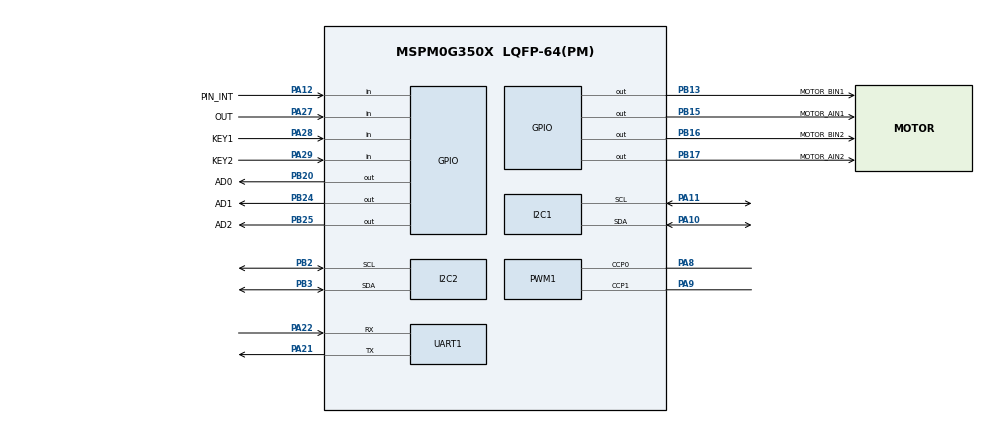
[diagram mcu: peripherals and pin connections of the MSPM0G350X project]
/**
 * @cliArgs --device "MSPM0G350X" --part "Default" --package "LQFP-64(PM)" --product "mspm0_sdk@2.10.00.04"
 * @versions {"tool":"1.26.2+4477"}
 */

/**
 * Import the modules used in this configuration.
 */
const GPIO   = scripting.addModule("/ti/driverlib/GPIO", {}, false);
const GPIO1  = GPIO.addInstance();
const GPIO2  = GPIO.addInstance();
const GPIO3  = GPIO.addInstance();
const GPIO4  = GPIO.addInstance();
const GPIO5  = GPIO.addInstance();
const GPIO6  = GPIO.addInstance();
const I2C    = scripting.addModule("/ti/driverlib/I2C", {}, false);
const I2C1   = I2C.addInstance();
const I2C2   = I2C.addInstance();
const PWM    = scripting.addModule("/ti/driverlib/PWM", {}, false);
const PWM1   = PWM.addInstance();
const SYSCTL = scripting.addModule("/ti/driverlib/SYSCTL");
const TIMER  = scripting.addModule("/ti/driverlib/TIMER", {}, false);
const TIMER1 = TIMER.addInstance();
const UART   = scripting.addModule("/ti/driverlib/UART", {}, false);
const UART1  = UART.addInstance();

/**
 * Write custom configuration values to the imported modules.
 */
GPIO1.$name                              = "KEY_INPUT";
GPIO1.port                               = "PORTA";
GPIO1.associatedPins.create(2);
GPIO1.associatedPins[0].$name            = "KEY1";
GPIO1.associatedPins[0].direction        = "INPUT";
GPIO1.associatedPins[0].internalResistor = "PULL_UP";
GPIO1.associatedPins[0].pin.$assign      = "PA28";
GPIO1.associatedPins[1].$name            = "KEY2";
GPIO1.associatedPins[1].direction        = "INPUT";
GPIO1.associatedPins[1].internalResistor = "PULL_UP";
GPIO1.associatedPins[1].pin.$assign      = "PA29";

const Board = scripting.addModule("/ti/driverlib/Board", {}, false);

GPIO2.$name                         = "MOTOR_AIN";
GPIO2.port                          = "PORTB";
GPIO2.associatedPins.create(2);
GPIO2.associatedPins[0].$name       = "MOTOR_AIN1";
GPIO2.associatedPins[0].pin.$assign = "PB15";
GPIO2.associatedPins[1].$name       = "MOTOR_AIN2";
GPIO2.associatedPins[1].pin.$assign = "PB17";

GPIO3.$name                         = "MOTOR_BIN";
GPIO3.port                          = "PORTB";
GPIO3.associatedPins.create(2);
GPIO3.associatedPins[0].$name       = "MOTOR_BIN1";
GPIO3.associatedPins[0].pin.$assign = "PB13";
GPIO3.associatedPins[1].$name       = "MOTOR_BIN2";
GPIO3.associatedPins[1].pin.$assign = "PB16";

GPIO4.$name                         = "Gray_Address";
GPIO4.port                          = "PORTB";
GPIO4.associatedPins.create(3);
GPIO4.associatedPins[0].$name       = "AD0";
GPIO4.associatedPins[0].pin.$assign = "PB20";
GPIO4.associatedPins[1].$name       = "AD1";
GPIO4.associatedPins[1].pin.$assign = "PB24";
GPIO4.associatedPins[2].$name       = "AD2";
GPIO4.associatedPins[2].pin.$assign = "PB25";

GPIO5.$name                         = "Gray_OUT";
GPIO5.port                          = "PORTA";
GPIO5.associatedPins[0].$name       = "OUT";
GPIO5.associatedPins[0].direction   = "INPUT";
GPIO5.associatedPins[0].pin.$assign = "PA27";

GPIO6.$name                         = "GPIO_MPU6050";
GPIO6.port                          = "PORTA";
GPIO6.associatedPins[0].$name       = "PIN_INT";
GPIO6.associatedPins[0].direction   = "INPUT";
GPIO6.associatedPins[0].pin.$assign = "PA12";

I2C1.$name                             = "I2C_OLED";
I2C1.basicEnableController             = true;
I2C1.basicControllerStandardBusSpeed   = "Fast";
I2C1.peripheral.$assign                = "I2C0";
I2C1.peripheral.sdaPin.$assign         = "PA10";
I2C1.peripheral.sclPin.$assign         = "PA11";
I2C1.sdaPinConfig.hideOutputInversion  = scripting.forceWrite(false);
I2C1.sdaPinConfig.onlyInternalResistor = scripting.forceWrite(false);
I2C1.sdaPinConfig.passedPeripheralType = scripting.forceWrite("Digital");
I2C1.sdaPinConfig.$name                = "ti_driverlib_gpio_GPIOPinGeneric2";
I2C1.sclPinConfig.hideOutputInversion  = scripting.forceWrite(false);
I2C1.sclPinConfig.onlyInternalResistor = scripting.forceWrite(false);
I2C1.sclPinConfig.passedPeripheralType = scripting.forceWrite("Digital");
I2C1.sclPinConfig.$name                = "ti_driverlib_gpio_GPIOPinGeneric3";

I2C2.$name                             = "I2C_MPU6050";
I2C2.basicEnableController             = true;
I2C2.basicControllerStandardBusSpeed   = "Fast";
I2C2.peripheral.$assign                = "I2C1";
I2C2.peripheral.sdaPin.$assign         = "PB3";
I2C2.peripheral.sclPin.$assign         = "PB2";
I2C2.sdaPinConfig.hideOutputInversion  = scripting.forceWrite(false);
I2C2.sdaPinConfig.onlyInternalResistor = scripting.forceWrite(false);
I2C2.sdaPinConfig.passedPeripheralType = scripting.forceWrite("Digital");
I2C2.sdaPinConfig.$name                = "ti_driverlib_gpio_GPIOPinGeneric4";
I2C2.sclPinConfig.hideOutputInversion  = scripting.forceWrite(false);
I2C2.sclPinConfig.onlyInternalResistor = scripting.forceWrite(false);
I2C2.sclPinConfig.passedPeripheralType = scripting.forceWrite("Digital");
I2C2.sclPinConfig.$name                = "ti_driverlib_gpio_GPIOPinGeneric5";

PWM1.$name                              = "PWM_MOTOR";
PWM1.pwmMode                            = "EDGE_ALIGN_UP";
PWM1.timerStartTimer                    = true;
PWM1.peripheral.$assign                 = "TIMA0";
PWM1.peripheral.ccp0Pin.$assign         = "PA8";
PWM1.peripheral.ccp1Pin.$assign         = "PA9";
PWM1.PWM_CHANNEL_0.$name                = "ti_driverlib_pwm_PWMTimerCC0";
PWM1.PWM_CHANNEL_0.dutyCycle            = 0;
PWM1.PWM_CHANNEL_1.$name                = "ti_driverlib_pwm_PWMTimerCC1";
PWM1.ccp0PinConfig.direction            = scripting.forceWrite("OUTPUT");
PWM1.ccp0PinConfig.hideOutputInversion  = scripting.forceWrite(false);
PWM1.ccp0PinConfig.onlyInternalResistor = scripting.forceWrite(false);
PWM1.ccp0PinConfig.passedPeripheralType = scripting.forceWrite("Digital");
PWM1.ccp0PinConfig.$name                = "ti_driverlib_gpio_GPIOPinGeneric0";
PWM1.ccp1PinConfig.direction            = scripting.forceWrite("OUTPUT");
PWM1.ccp1PinConfig.hideOutputInversion  = scripting.forceWrite(false);
PWM1.ccp1PinConfig.onlyInternalResistor = scripting.forceWrite(false);
PWM1.ccp1PinConfig.passedPeripheralType = scripting.forceWrite("Digital");
PWM1.ccp1PinConfig.$name                = "ti_driverlib_gpio_GPIOPinGeneric1";

SYSCTL.forceDefaultClkConfig = true;

TIMER1.timerMode          = "PERIODIC";
TIMER1.timerStartTimer    = true;
TIMER1.$name              = "CONTROL_TIMER";
TIMER1.timerPeriod        = "10ms";
TIMER1.timerClkDiv        = 8;
TIMER1.interrupts         = ["ZERO"];
TIMER1.interruptPriority  = "2";
TIMER1.peripheral.$assign = "TIMA1";

UART1.$name                    = "UART_0";
UART1.targetBaudRate           = 115200;
UART1.peripheral.rxPin.$assign = "PA22";
UART1.peripheral.txPin.$assign = "PA21";
UART1.txPinConfig.$name        = "ti_driverlib_gpio_GPIOPinGeneric6";
UART1.rxPinConfig.$name        = "ti_driverlib_gpio_GPIOPinGeneric7";

/**
 * Pinmux solution for unlocked pins/peripherals. This ensures that minor changes to the automatic solver in a future
 * version of the tool will not impact the pinmux you originally saw.  These lines can be completely deleted in order to
 * re-solve from scratch.
 */
Board.peripheral.$suggestSolution            = "DEBUGSS";
Board.peripheral.swclkPin.$suggestSolution   = "PA20";
Board.peripheral.swdioPin.$suggestSolution   = "PA19";
SYSCTL.peripheral.$suggestSolution           = "SYSCTL";
UART1.peripheral.$suggestSolution            = "UART2";
